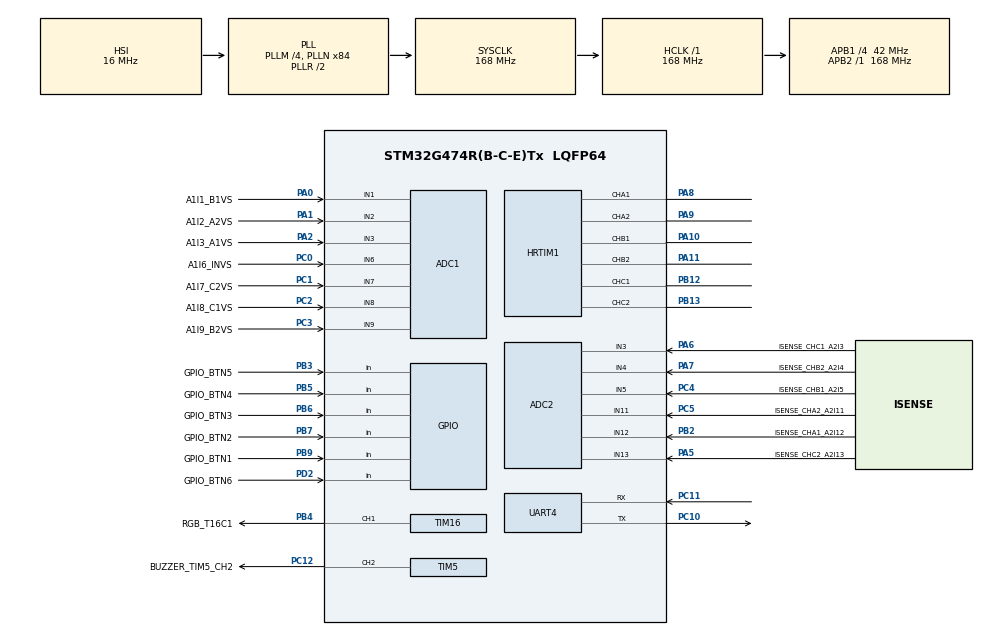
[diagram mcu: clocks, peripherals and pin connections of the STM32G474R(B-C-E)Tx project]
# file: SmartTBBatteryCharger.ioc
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ADC1.Channel-0\#ChannelRegularConversion=ADC_CHANNEL_3
ADC1.Channel-1\#ChannelRegularConversion=ADC_CHANNEL_2
ADC1.Channel-2\#ChannelRegularConversion=ADC_CHANNEL_1
ADC1.Channel-3\#ChannelRegularConversion=ADC_CHANNEL_9
ADC1.Channel-4\#ChannelRegularConversion=ADC_CHANNEL_8
ADC1.Channel-5\#ChannelRegularConversion=ADC_CHANNEL_7
ADC1.Channel-6\#ChannelRegularConversion=ADC_CHANNEL_6
ADC1.ContinuousConvMode=DISABLE
ADC1.DMAContinuousRequests=ENABLE
ADC1.DiscontinuousConvMode=ENABLE
ADC1.EOCSelection=ADC_EOC_SEQ_CONV
ADC1.ExternalTrigConv=ADC_EXTERNALTRIG_HRTIM_TRG6
ADC1.NbrOfConversion=7
ADC1.NbrOfConversionFlag=1
ADC1.NbrOfDiscConversion=7
ADC1.OffsetNumber-0\#ChannelRegularConversion=ADC_OFFSET_NONE
ADC1.OffsetNumber-1\#ChannelRegularConversion=ADC_OFFSET_NONE
ADC1.OffsetNumber-2\#ChannelRegularConversion=ADC_OFFSET_NONE
ADC1.OffsetNumber-3\#ChannelRegularConversion=ADC_OFFSET_NONE
ADC1.OffsetNumber-4\#ChannelRegularConversion=ADC_OFFSET_NONE
ADC1.OffsetNumber-5\#ChannelRegularConversion=ADC_OFFSET_NONE
ADC1.OffsetNumber-6\#ChannelRegularConversion=ADC_OFFSET_NONE
ADC1.Overrun=ADC_OVR_DATA_OVERWRITTEN
ADC1.Rank-0\#ChannelRegularConversion=1
ADC1.Rank-1\#ChannelRegularConversion=2
ADC1.Rank-2\#ChannelRegularConversion=3
ADC1.Rank-3\#ChannelRegularConversion=4
ADC1.Rank-4\#ChannelRegularConversion=5
ADC1.Rank-5\#ChannelRegularConversion=6
ADC1.Rank-6\#ChannelRegularConversion=7
ADC1.SamplingTime-0\#ChannelRegularConversion=ADC_SAMPLETIME_12CYCLES_5
ADC1.SamplingTime-1\#ChannelRegularConversion=ADC_SAMPLETIME_12CYCLES_5
ADC1.SamplingTime-2\#ChannelRegularConversion=ADC_SAMPLETIME_12CYCLES_5
ADC1.SamplingTime-3\#ChannelRegularConversion=ADC_SAMPLETIME_12CYCLES_5
ADC1.SamplingTime-4\#ChannelRegularConversion=ADC_SAMPLETIME_12CYCLES_5
ADC1.SamplingTime-5\#ChannelRegularConversion=ADC_SAMPLETIME_12CYCLES_5
ADC1.SamplingTime-6\#ChannelRegularConversion=ADC_SAMPLETIME_12CYCLES_5
ADC1.master=1
ADC2.Channel-2\#ChannelRegularConversion=ADC_CHANNEL_12
ADC2.Channel-3\#ChannelRegularConversion=ADC_CHANNEL_11
ADC2.Channel-4\#ChannelRegularConversion=ADC_CHANNEL_5
ADC2.Channel-5\#ChannelRegularConversion=ADC_CHANNEL_4
ADC2.Channel-6\#ChannelRegularConversion=ADC_CHANNEL_3
ADC2.Channel-7\#ChannelRegularConversion=ADC_CHANNEL_13
ADC2.DMAContinuousRequests=ENABLE
ADC2.DiscontinuousConvMode=ENABLE
ADC2.EOCSelection=ADC_EOC_SEQ_CONV
ADC2.ExternalTrigConv=ADC_EXTERNALTRIG_HRTIM_TRG6
ADC2.NbrOfConversion=6
ADC2.NbrOfConversionFlag=1
ADC2.NbrOfDiscConversion=6
ADC2.OffsetNumber-2\#ChannelRegularConversion=ADC_OFFSET_NONE
ADC2.OffsetNumber-3\#ChannelRegularConversion=ADC_OFFSET_NONE
ADC2.OffsetNumber-4\#ChannelRegularConversion=ADC_OFFSET_NONE
ADC2.OffsetNumber-5\#ChannelRegularConversion=ADC_OFFSET_NONE
ADC2.OffsetNumber-6\#ChannelRegularConversion=ADC_OFFSET_NONE
ADC2.OffsetNumber-7\#ChannelRegularConversion=ADC_OFFSET_NONE
ADC2.Overrun=ADC_OVR_DATA_OVERWRITTEN
ADC2.Rank-2\#ChannelRegularConversion=1
ADC2.Rank-3\#ChannelRegularConversion=2
ADC2.Rank-4\#ChannelRegularConversion=3
ADC2.Rank-5\#ChannelRegularConversion=4
ADC2.Rank-6\#ChannelRegularConversion=5
ADC2.Rank-7\#ChannelRegularConversion=6
ADC2.SamplingTime-2\#ChannelRegularConversion=ADC_SAMPLETIME_12CYCLES_5
ADC2.SamplingTime-3\#ChannelRegularConversion=ADC_SAMPLETIME_12CYCLES_5
ADC2.SamplingTime-4\#ChannelRegularConversion=ADC_SAMPLETIME_12CYCLES_5
ADC2.SamplingTime-5\#ChannelRegularConversion=ADC_SAMPLETIME_12CYCLES_5
ADC2.SamplingTime-6\#ChannelRegularConversion=ADC_SAMPLETIME_12CYCLES_5
ADC2.SamplingTime-7\#ChannelRegularConversion=ADC_SAMPLETIME_12CYCLES_5
Dma.ADC1.0.Direction=DMA_PERIPH_TO_MEMORY
Dma.ADC1.0.EventEnable=DISABLE
Dma.ADC1.0.Instance=DMA1_Channel4
Dma.ADC1.0.MemDataAlignment=DMA_MDATAALIGN_HALFWORD
Dma.ADC1.0.MemInc=DMA_MINC_ENABLE
Dma.ADC1.0.Mode=DMA_CIRCULAR
Dma.ADC1.0.PeriphDataAlignment=DMA_PDATAALIGN_HALFWORD
Dma.ADC1.0.PeriphInc=DMA_PINC_DISABLE
Dma.ADC1.0.Polarity=HAL_DMAMUX_REQ_GEN_RISING
Dma.ADC1.0.Priority=DMA_PRIORITY_HIGH
Dma.ADC1.0.RequestNumber=1
Dma.ADC1.0.SignalID=NONE
Dma.ADC1.0.SyncEnable=DISABLE
Dma.ADC1.0.SyncPolarity=HAL_DMAMUX_SYNC_NO_EVENT
Dma.ADC1.0.SyncRequestNumber=1
Dma.ADC1.0.SyncSignalID=NONE
Dma.ADC2.1.Direction=DMA_PERIPH_TO_MEMORY
Dma.ADC2.1.EventEnable=DISABLE
Dma.ADC2.1.Instance=DMA1_Channel6
Dma.ADC2.1.MemDataAlignment=DMA_MDATAALIGN_HALFWORD
Dma.ADC2.1.MemInc=DMA_MINC_ENABLE
Dma.ADC2.1.Mode=DMA_CIRCULAR
Dma.ADC2.1.PeriphDataAlignment=DMA_PDATAALIGN_HALFWORD
Dma.ADC2.1.PeriphInc=DMA_PINC_DISABLE
Dma.ADC2.1.Polarity=HAL_DMAMUX_REQ_GEN_RISING
Dma.ADC2.1.Priority=DMA_PRIORITY_VERY_HIGH
Dma.ADC2.1.RequestNumber=1
Dma.ADC2.1.SignalID=NONE
Dma.ADC2.1.SyncEnable=DISABLE
Dma.ADC2.1.SyncPolarity=HAL_DMAMUX_SYNC_NO_EVENT
Dma.ADC2.1.SyncRequestNumber=1
Dma.ADC2.1.SyncSignalID=NONE
Dma.Request0=ADC1
Dma.Request1=ADC2
HRTIM1.ADCTrigger_Id6=HRTIM_ADCTRIGGER_6
HRTIM1.CompareUnit1-Output_TA1TA2=HRTIM_COMPAREUNIT_1
HRTIM1.CompareUnit1-Output_TB1TB2=HRTIM_COMPAREUNIT_1
HRTIM1.CompareUnit1-Output_TC1TC2=HRTIM_COMPAREUNIT_1
HRTIM1.CompareUnit2-MasterTimer=HRTIM_COMPAREUNIT_2
HRTIM1.CompareUnit2-Output_TA1TA2=HRTIM_COMPAREUNIT_2
HRTIM1.CompareUnit2-Output_TB1TB2=HRTIM_COMPAREUNIT_2
HRTIM1.CompareUnit2-Output_TC1TC2=HRTIM_COMPAREUNIT_2
HRTIM1.CompareUnit3-Output_TA1TA2=HRTIM_COMPAREUNIT_3
HRTIM1.CompareUnit3-Output_TB1TB2=HRTIM_COMPAREUNIT_3
HRTIM1.CompareUnit3-Output_TC1TC2=HRTIM_COMPAREUNIT_3
HRTIM1.CompareUnit4-Output_TA1TA2=HRTIM_COMPAREUNIT_4
HRTIM1.CompareUnit4-Output_TB1TB2=HRTIM_COMPAREUNIT_4
HRTIM1.CompareUnit4-Output_TC1TC2=HRTIM_COMPAREUNIT_4
HRTIM1.CompareValue2-MasterTimer=53760 / 2 - 500
HRTIM1.InterruptRequests1_Master=HRTIM_MASTER_IT_MREP
HRTIM1.NumberInterruptRequests_Master-MasterTimer=1
HRTIM1.NumberResetSource1-Output_TA1TA2=1
HRTIM1.NumberResetSource1-Output_TB1TB2=1
HRTIM1.NumberResetSource1-Output_TC1TC2=1
HRTIM1.NumberResetSource2_TA=1
HRTIM1.NumberResetSource2_TB=1
HRTIM1.NumberResetSource2_TC=1
HRTIM1.NumberResetTrigger-Output_TA1TA2=1
HRTIM1.NumberResetTrigger-Output_TB1TB2=1
HRTIM1.NumberResetTrigger-Output_TC1TC2=1
HRTIM1.NumberSetSource1-Output_TA1TA2=1
HRTIM1.NumberSetSource1-Output_TB1TB2=1
HRTIM1.NumberSetSource1-Output_TC1TC2=1
HRTIM1.NumberSetSource2_TA=1
HRTIM1.NumberSetSource2_TB=1
HRTIM1.NumberSetSource2_TC=1
HRTIM1.ORingUpdateSource_ADCTrigger6=HRTIM_ADCTRIGGERUPDATE_TIMER_B
HRTIM1.Periode_MASTER=53760
HRTIM1.Periode_TA=53760
HRTIM1.Periode_TB=53760
HRTIM1.Periode_TC=53760
HRTIM1.PreloadEnable-MasterTimer=HRTIM_PRELOAD_ENABLED
HRTIM1.PreloadEnable-Output_TA1TA2=HRTIM_PRELOAD_ENABLED
HRTIM1.PreloadEnable-Output_TB1TB2=HRTIM_PRELOAD_ENABLED
HRTIM1.PreloadEnable-Output_TC1TC2=HRTIM_PRELOAD_ENABLED
HRTIM1.PrescalerRatio_MASTER=HRTIM_PRESCALERRATIO_MUL32
HRTIM1.PrescalerRatio_TA=HRTIM_PRESCALERRATIO_MUL32
HRTIM1.PrescalerRatio_TB=HRTIM_PRESCALERRATIO_MUL32
HRTIM1.PrescalerRatio_TC=HRTIM_PRESCALERRATIO_MUL32
HRTIM1.RepetitionCounter-MasterTimer=4-1
HRTIM1.RepetitionCounter-Output_TA1TA2=0
HRTIM1.RepetitionUpdate-MasterTimer=HRTIM_UPDATEONREPETITION_ENABLED
HRTIM1.RepetitionUpdate-Output_TA1TA2=HRTIM_UPDATEONREPETITION_ENABLED
HRTIM1.RepetitionUpdate-Output_TB1TB2=HRTIM_UPDATEONREPETITION_ENABLED
HRTIM1.RepetitionUpdate-Output_TC1TC2=HRTIM_UPDATEONREPETITION_ENABLED
HRTIM1.ResetOutput1_Source1-Output_TA1TA2=HRTIM_OUTPUTRESET_TIMCMP3
HRTIM1.ResetOutput1_Source1-Output_TB1TB2=HRTIM_OUTPUTRESET_TIMCMP3
HRTIM1.ResetOutput1_Source1-Output_TC1TC2=HRTIM_OUTPUTRESET_TIMCMP3
HRTIM1.ResetOutput2_Source1-Output_TA1TA2=HRTIM_OUTPUTRESET_TIMCMP4
HRTIM1.ResetOutput2_Source1-Output_TB1TB2=HRTIM_OUTPUTRESET_TIMCMP4
HRTIM1.ResetOutput2_Source1-Output_TC1TC2=HRTIM_OUTPUTRESET_TIMCMP4
HRTIM1.ResetTrigger1-Output_TA1TA2=HRTIM_TIMRESETTRIGGER_MASTER_PER
HRTIM1.ResetTrigger1-Output_TB1TB2=HRTIM_TIMRESETTRIGGER_MASTER_PER
HRTIM1.ResetTrigger1-Output_TC1TC2=HRTIM_TIMRESETTRIGGER_MASTER_PER
HRTIM1.SetOutput1_Source1-Output_TA1TA2=HRTIM_OUTPUTSET_TIMCMP1
HRTIM1.SetOutput1_Source1-Output_TB1TB2=HRTIM_OUTPUTSET_TIMCMP1
HRTIM1.SetOutput1_Source1-Output_TC1TC2=HRTIM_OUTPUTSET_TIMCMP1
HRTIM1.SetOutput2_Source1-Output_TA1TA2=HRTIM_OUTPUTSET_TIMCMP2
HRTIM1.SetOutput2_Source1-Output_TB1TB2=HRTIM_OUTPUTSET_TIMCMP2
HRTIM1.SetOutput2_Source1-Output_TC1TC2=HRTIM_OUTPUTSET_TIMCMP2
HRTIM1.Source_ADCTrigger6=HRTIM_ADCTRIGGEREVENT6810_MASTER_CMP2
Mcu.Family=STM32G4
Mcu.Name=STM32G474R(B-C-E)Tx
Mcu.Package=LQFP64
NVIC.DMA1_Channel4_IRQn=true\:0\:0\:false\:false\:true\:false\:true\:true
NVIC.DMA1_Channel6_IRQn=true\:0\:0\:false\:false\:true\:false\:true\:true
NVIC.HRTIM1_Master_IRQn=true\:0\:0\:false\:false\:false\:true\:true\:true
NVIC.PriorityGroup=NVIC_PRIORITYGROUP_4
PA0.GPIO_Label=A1I1_B1VS
PA0.Mode=IN1-Single-Ended
PA0.Signal=ADC1_IN1
PA1.GPIO_Label=A1I2_A2VS
PA1.Mode=IN2-Single-Ended
PA1.Signal=ADC1_IN2
PA10.Mode=Output_TB1TB2
PA10.Signal=HRTIM1_CHB1
PA11.Mode=Output_TB1TB2
PA11.Signal=HRTIM1_CHB2
PA13.Mode=Serial_Wire
PA13.Signal=SYS_JTMS-SWDIO
PA14.Mode=Serial_Wire
PA14.Signal=SYS_JTCK-SWCLK
PA2.GPIO_Label=A1I3_A1VS
PA2.Mode=IN3-Single-Ended
PA2.Signal=ADC1_IN3
PA5.GPIO_Label=ISENSE_CHC2_A2I13
PA5.Mode=IN13-Single-Ended
PA5.Signal=ADC2_IN13
PA6.GPIO_Label=ISENSE_CHC1_A2I3
PA6.Mode=IN3-Single-Ended
PA6.Signal=ADC2_IN3
PA7.GPIO_Label=ISENSE_CHB2_A2I4
PA7.Mode=IN4-Single-Ended
PA7.Signal=ADC2_IN4
PA8.Mode=Output_TA1TA2
PA8.Signal=HRTIM1_CHA1
PA9.Mode=Output_TA1TA2
PA9.Signal=HRTIM1_CHA2
PB12.Mode=Output_TC1TC2
PB12.Signal=HRTIM1_CHC1
PB13.Mode=Output_TC1TC2
PB13.Signal=HRTIM1_CHC2
PB2.GPIO_Label=ISENSE_CHA1_A2I12
PB2.Mode=IN12-Single-Ended
PB2.Signal=ADC2_IN12
PB3.GPIO_Label=GPIO_BTN5
PB3.Signal=GPIO_Input
PB4.GPIO_Label=RGB_T16C1
PB4.Signal=S_TIM16_CH1
PB5.GPIO_Label=GPIO_BTN4
PB5.Signal=GPIO_Input
PB6.GPIO_Label=GPIO_BTN3
PB6.Signal=GPIO_Input
PB7.GPIO_Label=GPIO_BTN2
PB7.Signal=GPIO_Input
PB9.GPIO_Label=GPIO_BTN1
PB9.Signal=GPIO_Input
PC0.GPIO_Label=A1I6_INVS
PC0.Mode=IN6-Single-Ended
PC0.Signal=ADC1_IN6
PC1.GPIO_Label=A1I7_C2VS
PC1.Mode=IN7-Single-Ended
PC1.Signal=ADC1_IN7
PC10.Mode=Asynchronous
PC10.Signal=UART4_TX
PC11.Mode=Asynchronous
PC11.Signal=UART4_RX
PC12.GPIO_Label=BUZZER_TIM5_CH2
PC12.Signal=S_TIM5_CH2
PC2.GPIO_Label=A1I8_C1VS
PC2.Mode=IN8-Single-Ended
PC2.Signal=ADC1_IN8
PC3.GPIO_Label=A1I9_B2VS
PC3.Mode=IN9-Single-Ended
PC3.Signal=ADC1_IN9
PC4.GPIO_Label=ISENSE_CHB1_A2I5
PC4.Mode=IN5-Single-Ended
PC4.Signal=ADC2_IN5
PC5.GPIO_Label=ISENSE_CHA2_A2I11
PC5.Mode=IN11-Single-Ended
PC5.Signal=ADC2_IN11
PD2.GPIO_Label=GPIO_BTN6
PD2.Signal=GPIO_Input
ProjectManager.HeapSize=0x200
ProjectManager.StackSize=0x400
ProjectManager.TargetToolchain=Makefile
RCC.ADC12Freq_Value=168000000
RCC.ADC345Freq_Value=168000000
RCC.AHBFreq_Value=168000000
RCC.APB1CLKDivider=RCC_HCLK_DIV4
RCC.APB1Freq_Value=42000000
RCC.APB1TimFreq_Value=84000000
RCC.APB2Freq_Value=168000000
RCC.APB2TimFreq_Value=168000000
RCC.CortexFreq_Value=168000000
RCC.EXTERNAL_CLOCK_VALUE=12288000
RCC.HCLKFreq_Value=168000000
RCC.HSE_VALUE=8000000
RCC.HSI48_VALUE=48000000
RCC.HSI_VALUE=16000000
RCC.LSE_VALUE=32768
RCC.PLLM=RCC_PLLM_DIV4
RCC.PLLN=84
RCC.SYSCLKFreq_VALUE=168000000
RCC.SYSCLKSource=RCC_SYSCLKSOURCE_PLLCLK
RCC.USBFreq_Value=168000000
RCC.VCOOutputFreq_Value=336000000
SH.S_TIM16_CH1.0=TIM16_CH1,PWM Generation1 CH1
SH.S_TIM5_CH2.0=TIM5_CH2,PWM Generation2 CH2
STMicroelectronics.X-CUBE-ALGOBUILD.1.4.0.LibraryCcDSPOoLibraryJjDSPOoLibrary=true
SYS.VoltageScaling=SYSCFG_VREFBUF_VOLTAGE_SCALE2
TIM16.Channel=TIM_CHANNEL_1
TIM5.Channel-PWM\ Generation2\ CH2=TIM_CHANNEL_2
VP_HRTIM1_VS_hrtimMasterTimerNoOutput.Mode=MasterTimer
VP_STMicroelectronics.X-CUBE-ALGOBUILD_VS_DSPOoLibraryJjLibrary_1.4.0_1.4.0.Mode=DSPOoLibraryJjLibrary
VP_SYS_VS_DBSignals.Mode=DisableDeadBatterySignals
VP_TIM16_VS_ClockSourceINT.Mode=Enable_Timer
VREF+.Mode=InternalMode
VREF+.Signal=VREFBUF_OUT
board=custom

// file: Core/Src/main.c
/* USER CODE BEGIN Header */
/**
  ******************************************************************************
  * @file           : main.c
  * @brief          : Main program body
  ******************************************************************************
  * @attention
  *
  * Copyright (c) 2024 STMicroelectronics.
  * All rights reserved.
  *
  * This software is licensed under terms that can be found in the LICENSE file
  * in the root directory of this software component.
  * If no LICENSE file comes with this software, it is provided AS-IS.
  *
  ******************************************************************************
  */
/* USER CODE END Header */
#include "main.h"
#include "adc.h"
#include "dma.h"
#include "hrtim.h"
#include "tim.h"
#include "usart.h"
#include "gpio.h"

void SystemClock_Config(void);

int main(void)
{

  /* MCU Configuration--------------------------------------------------------*/

  /* Reset of all peripherals, Initializes the Flash interface and the Systick. */
  HAL_Init();

  /* Configure the system clock */
  SystemClock_Config();

  /* Initialize all configured peripherals */
  MX_GPIO_Init();
  MX_DMA_Init();
  MX_ADC1_Init();
  MX_HRTIM1_Init();
  MX_TIM5_Init();
  MX_TIM16_Init();
  MX_UART4_Init();
  MX_ADC2_Init();
  /* USER CODE BEGIN 2 */
  extern void systemStart(void );
  systemStart();
  /* USER CODE END 2 */

  /* Infinite loop */
  while (1)
  {

  }
}

void SystemClock_Config(void)
{
  RCC_OscInitTypeDef RCC_OscInitStruct = {0};
  RCC_ClkInitTypeDef RCC_ClkInitStruct = {0};

  /** Configure the main internal regulator output voltage
  */
  HAL_PWREx_ControlVoltageScaling(PWR_REGULATOR_VOLTAGE_SCALE1_BOOST);

  /** Initializes the RCC Oscillators according to the specified parameters
  * in the RCC_OscInitTypeDef structure.
  */
  RCC_OscInitStruct.OscillatorType = RCC_OSCILLATORTYPE_HSI;
  RCC_OscInitStruct.HSIState = RCC_HSI_ON;
  RCC_OscInitStruct.HSICalibrationValue = RCC_HSICALIBRATION_DEFAULT;
  RCC_OscInitStruct.PLL.PLLState = RCC_PLL_ON;
  RCC_OscInitStruct.PLL.PLLSource = RCC_PLLSOURCE_HSI;
  RCC_OscInitStruct.PLL.PLLM = RCC_PLLM_DIV4;
  RCC_OscInitStruct.PLL.PLLN = 84;
  RCC_OscInitStruct.PLL.PLLP = RCC_PLLP_DIV2;
  RCC_OscInitStruct.PLL.PLLQ = RCC_PLLQ_DIV2;
  RCC_OscInitStruct.PLL.PLLR = RCC_PLLR_DIV2;
  if (HAL_RCC_OscConfig(&RCC_OscInitStruct) != HAL_OK)
  {
    Error_Handler();
  }

  /** Initializes the CPU, AHB and APB buses clocks
  */
  RCC_ClkInitStruct.ClockType = RCC_CLOCKTYPE_HCLK|RCC_CLOCKTYPE_SYSCLK
                              |RCC_CLOCKTYPE_PCLK1|RCC_CLOCKTYPE_PCLK2;
  RCC_ClkInitStruct.SYSCLKSource = RCC_SYSCLKSOURCE_PLLCLK;
  RCC_ClkInitStruct.AHBCLKDivider = RCC_SYSCLK_DIV1;
  RCC_ClkInitStruct.APB1CLKDivider = RCC_HCLK_DIV4;
  RCC_ClkInitStruct.APB2CLKDivider = RCC_HCLK_DIV1;

  if (HAL_RCC_ClockConfig(&RCC_ClkInitStruct, FLASH_LATENCY_4) != HAL_OK)
  {
    Error_Handler();
  }
}

void Error_Handler(void)
{
  __disable_irq();
  while (1)
  {
  }
}

#ifdef  USE_FULL_ASSERT
/**
  * @brief  Reports the name of the source file and the source line number
  *         where the assert_param error has occurred.
  * @param  file: pointer to the source file name
  * @param  line: assert_param error line source number
  * @retval None
  */
void assert_failed(uint8_t *file, uint32_t line)
{
  /* USER CODE BEGIN 6 */
  /* User can add his own implementation to report the file name and line number,
     ex: printf("Wrong parameters value: file %s on line %d\r\n", file, line) */
  __asm__("bkpt");
  /* USER CODE END 6 */
}
#endif /* USE_FULL_ASSERT */
